# DA14586 register map
Vendor: Dialog; Series: DA1458x; File version: 1.2
CPU: CM0 r1p0, little endian, MPU, FPU, 3 interrupt priority bits
Registers are 16-bit, read-write, reset 0x0 unless marked. A register's access mark holds for its fields unless they carry their own. Offsets are from the block's base; [hi:lo] are bit positions; 'fields as' and 'values as' point back to an identical list.

## r_rfcu580_nl01 — r_rfcu580_nl01 registers
Base 0x50002000
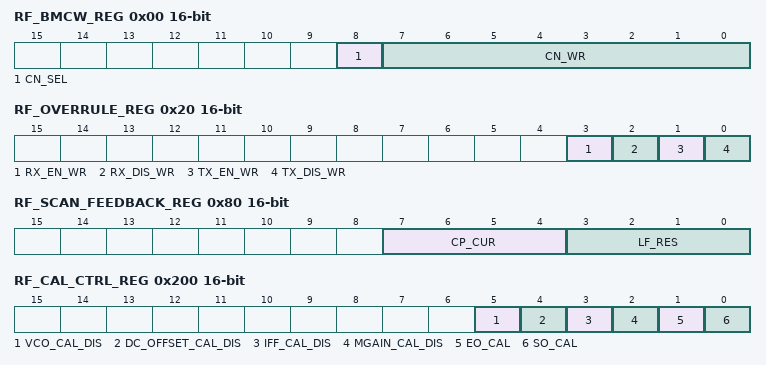
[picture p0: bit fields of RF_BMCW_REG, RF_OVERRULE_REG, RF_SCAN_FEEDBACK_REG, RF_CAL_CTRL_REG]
0x00 RF_BMCW_REG — Changed functionality of bits [7:6]
  [8] CN_SEL — Select between: 1 = use CN_WR as channel number 0 = use BLE Frequency word (normal function).
  [7:0] CN_WR — [7:6] = offset to RFCAL_CAP_WR, coarse calibraton LUT [5:0] = channel number
0x20 RF_OVERRULE_REG
  [3] RX_EN_WR — Enable rx_en
  [2] RX_DIS_WR — Disable rx_en
  [1] TX_EN_WR — Enable tx_en
  [0] TX_DIS_WR — Disable tx_en
0x40 RF_CALSTATE_REG
  [3:0] CALSTATE ro — Value of the calstate state machine
0x60 RF_CALCAP1_REG
  [15:0] VCO_CALCAP_LOW ro — Lowest 16 bits of vco_calcap
0x62 RF_CALCAP2_REG
  [1:0] VCO_CALCAP_HIGH ro — Highest 2 bits of vco_calcap.
0x80 RF_SCAN_FEEDBACK_REG
  [7:4] CP_CUR ro — Cp_cur value during scan.
  [3:0] LF_RES ro — Lf_res value during scan.
0x200 RF_CAL_CTRL_REG
  [5] VCO_CAL_DIS — Do not calibrate the VCO during Cal cycle
  [4] DC_OFFSET_CAL_DIS — Do not calibrate the VGA2 Offset during Cal cycle
  [3] IFF_CAL_DIS — Do not calibrate the IFF center frequency during Cal cycle
  [2] MGAIN_CAL_DIS — Do not calibrate the VCO and Modulation Gain during Cal cycle
  [1] EO_CAL ro — End of calibration trigger. Reading returns the eo_cal status signal which can be cleared by writing to RF_IRQ_CTRL_REG.EO_CAL_CLEAR
  [0] SO_CAL — Start of calibration trigger.Writing a 1 starts calibration.1Reading returns the calibration status (1 = busy calibrating).
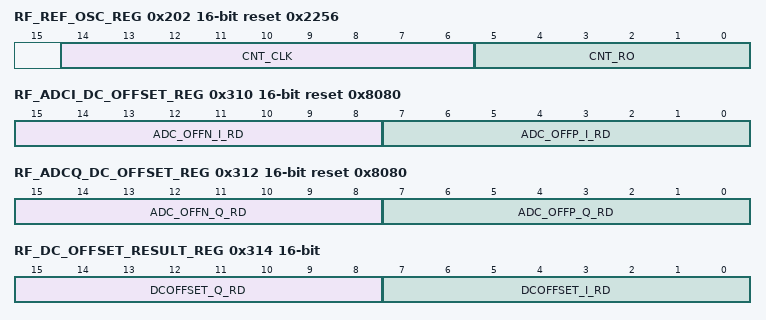
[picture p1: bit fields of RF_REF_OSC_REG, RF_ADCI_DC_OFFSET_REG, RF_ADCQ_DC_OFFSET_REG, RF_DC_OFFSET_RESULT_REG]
0x202 RF_REF_OSC_REG reset 0x2256
  [14:6] CNT_CLK — number of clock pulses corresponding to the value of CNT_RO
  [5:0] CNT_RO — number of reference oscillator periods that need to be counted
0x204 RF_IRQ_CTRL_REG reset 0x1
  [0] EO_CAL_CLEAR ro — Writing any value to this bit clears eo_cal interrupt.
0x300 RF_IFF_RESULT_REG reset 0x10 — Must be Retained
  [4:0] IF_CAL_CAP_RD ro — IF calibration result capacitance.
0x310 RF_ADCI_DC_OFFSET_REG reset 0x8080 — Must be Retained
  [15:8] ADC_OFFN_I_RD ro — DC offset compensation in the I path (inverting input) in sign-magnitude notarion (i.e. -31 : 1 : 31 mV)
  [7:0] ADC_OFFP_I_RD ro — DC offset compensation in the I path (non-inverting input) in sign-magnitude notarion (i.e. -31 : 1 : 31 mV)
0x312 RF_ADCQ_DC_OFFSET_REG reset 0x8080 — Must be Retained
  [15:8] ADC_OFFN_Q_RD ro — DC offset compensation in the Q path (inverting input) in sign-magnitude notarion (i.e. -31 : 1 : 31 mV)
  [7:0] ADC_OFFP_Q_RD ro — DC offset compensation in the Q path (non-inverting input) in sign-magnitude notarion (i.e. -31 : 1 : 31 mV)
0x314 RF_DC_OFFSET_RESULT_REG — Must be Retained
  [15:8] DCOFFSET_Q_RD ro — DC offset compensation value in Q channel valid when DCOFFSET_SEL = 0
  [7:0] DCOFFSET_I_RD ro — DC offset compensation value in I channel valid when DCOFFSET_SEL = 0.
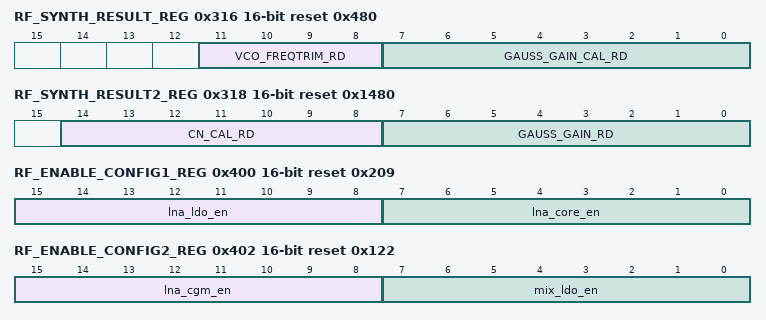
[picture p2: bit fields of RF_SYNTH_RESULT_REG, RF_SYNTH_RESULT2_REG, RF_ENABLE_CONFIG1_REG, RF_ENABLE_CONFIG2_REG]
0x316 RF_SYNTH_RESULT_REG reset 0x480 — Must be Retained
  [11:8] VCO_FREQTRIM_RD ro — Result of the VCO calibration (Not Retained)
  [7:0] GAUSS_GAIN_CAL_RD ro — Result of the modulation gain calibration (Retained)
0x318 RF_SYNTH_RESULT2_REG reset 0x1480 — Must be Retained
  [14:8] CN_CAL_RD ro — Result of the modulation gain calibration (Retained)
  [7:0] GAUSS_GAIN_RD ro — Modulation gain after trimming (Not Retained)
0x31A RF_SYNTH_RESULT3_REG reset 0xFFFF
  [15:0] MDSTATE_RD ro — Content of the calibration counter
0x400 RF_ENABLE_CONFIG1_REG reset 0x209
  [15:8] lna_ldo_en — Timing configuration for enable of the lna ldo
  [7:0] lna_core_en — Timing configuration for enable of the lna core
0x402 RF_ENABLE_CONFIG2_REG reset 0x122
  [15:8] lna_cgm_en — Timing configuration for enable of the lna cgm
  [7:0] mix_ldo_en — Timing configuration for enable of the mix ldo
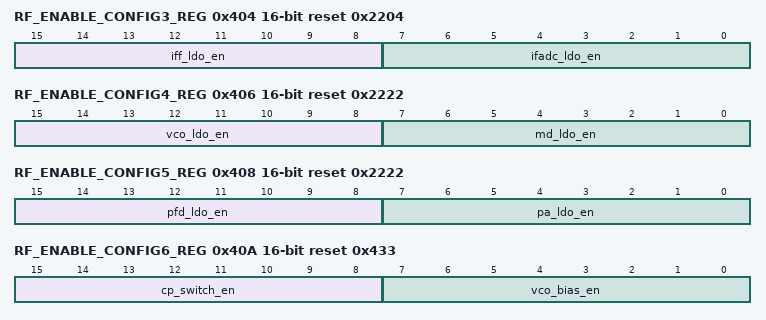
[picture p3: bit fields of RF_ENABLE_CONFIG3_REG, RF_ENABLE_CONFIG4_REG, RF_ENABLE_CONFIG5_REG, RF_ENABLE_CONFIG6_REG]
0x404 RF_ENABLE_CONFIG3_REG reset 0x2204
  [15:8] iff_ldo_en — Timing configuration for enable of the iff ldo
  [7:0] ifadc_ldo_en — Timing configuration for enable of the ifadc ldo
0x406 RF_ENABLE_CONFIG4_REG reset 0x2222
  [15:8] vco_ldo_en — Timing configuration for enable of the vco ldo
  [7:0] md_ldo_en — Timing configuration for enable of the md ldo
0x408 RF_ENABLE_CONFIG5_REG reset 0x2222
  [15:8] pfd_ldo_en — Timing configuration for enable of the pfd ldo
  [7:0] pa_ldo_en — Timing configuration for enable of the pa ldo
0x40A RF_ENABLE_CONFIG6_REG reset 0x433
  [15:8] cp_switch_en — Timing configuration for the dynamic CP current switching
  [7:0] vco_bias_en — Timing configuration for the VCO bias
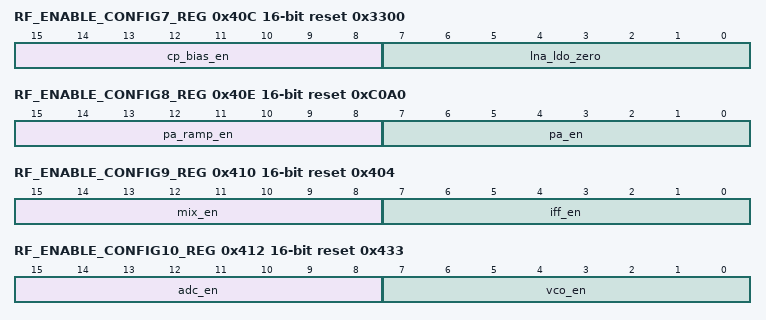
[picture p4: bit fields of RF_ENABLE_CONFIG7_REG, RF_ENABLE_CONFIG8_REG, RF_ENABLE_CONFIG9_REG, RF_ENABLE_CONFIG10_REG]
0x40C RF_ENABLE_CONFIG7_REG reset 0x3300
  [15:8] cp_bias_en — Timing configuration for enable of the CP bias
  [7:0] lna_ldo_zero — autozero control signal of the lna ldo
0x40E RF_ENABLE_CONFIG8_REG reset 0xC0A0
  [15:8] pa_ramp_en — Timing configuration for enable of the PA ramp
  [7:0] pa_en — Timing configuration for enable of the PA
0x410 RF_ENABLE_CONFIG9_REG reset 0x404
  [15:8] mix_en — Timing configuration for enable of the mixer
  [7:0] iff_en — Timing configuration for enable of the iff
0x412 RF_ENABLE_CONFIG10_REG reset 0x433
  [15:8] adc_en — Timing configuration for enable of the ADC
  [7:0] vco_en — Timing configuration for enable of the VCO
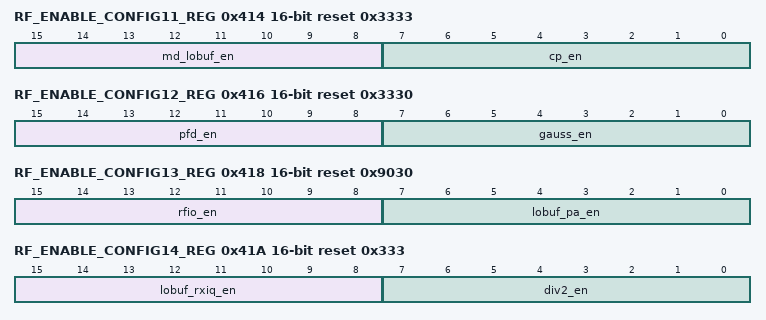
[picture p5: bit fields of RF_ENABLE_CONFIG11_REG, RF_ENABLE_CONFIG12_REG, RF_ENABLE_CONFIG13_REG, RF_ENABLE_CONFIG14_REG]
0x414 RF_ENABLE_CONFIG11_REG reset 0x3333
  [15:8] md_lobuf_en — Timing configuration for enable of main divider of the LO buffer
  [7:0] cp_en — Timing configuration for enable of CP
0x416 RF_ENABLE_CONFIG12_REG reset 0x3330
  [15:8] pfd_en — Timing configuration for the phase frequency detector
  [7:0] gauss_en — Timing configuration for the gauss module
0x418 RF_ENABLE_CONFIG13_REG reset 0x9030
  [15:8] rfio_en — Timing configuration for the rfio
  [7:0] lobuf_pa_en — Timing configuration for the PA lobuffer
0x41A RF_ENABLE_CONFIG14_REG reset 0x333
  [15:8] lobuf_rxiq_en — Timing configuration for the rxi lobuffer
  [7:0] div2_en — Timing configuration for the 2 divider
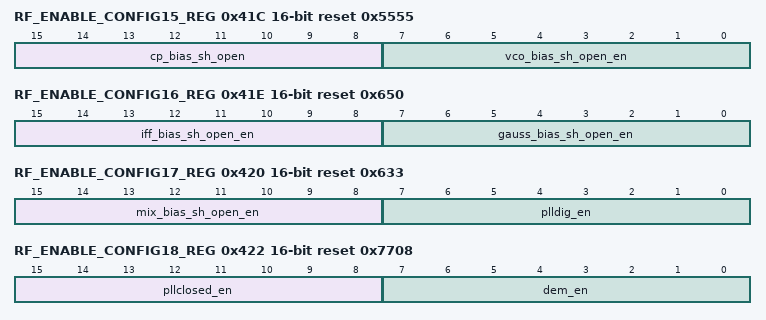
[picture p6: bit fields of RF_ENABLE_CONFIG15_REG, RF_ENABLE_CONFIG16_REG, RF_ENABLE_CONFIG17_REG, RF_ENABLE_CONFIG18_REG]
0x41C RF_ENABLE_CONFIG15_REG reset 0x5555
  [15:8] cp_bias_sh_open — Timing configuration for the CP bias S/H switch
  [7:0] vco_bias_sh_open_en — Timing configuration for the VCO bias S/H switch
0x41E RF_ENABLE_CONFIG16_REG reset 0x650
  [15:8] iff_bias_sh_open_en — Timing configuration for iffmix bias S/H switch
  [7:0] gauss_bias_sh_open_en — Timing configuration for gauss bias S/H switch
0x420 RF_ENABLE_CONFIG17_REG reset 0x633
  [15:8] mix_bias_sh_open_en — Timing configuration for pa bias S/H switch
  [7:0] plldig_en — Timing configuration for the plldig
0x422 RF_ENABLE_CONFIG18_REG reset 0x7708
  [15:8] pllclosed_en — Timing configuration for pllclosed
  [7:0] dem_en — Timing configuration for demodulator
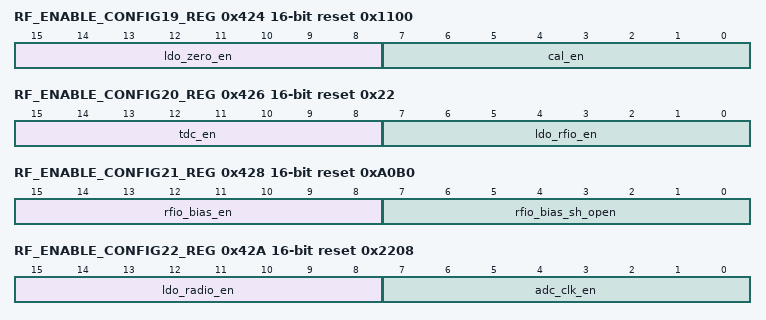
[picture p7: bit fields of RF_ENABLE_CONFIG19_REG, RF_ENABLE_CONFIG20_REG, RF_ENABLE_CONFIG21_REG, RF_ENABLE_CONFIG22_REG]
0x424 RF_ENABLE_CONFIG19_REG reset 0x1100
  [15:8] ldo_zero_en — Timing configuration for radio LDO auto zero enable
  [7:0] cal_en — Timing configuration for calibration slot
0x426 RF_ENABLE_CONFIG20_REG reset 0x22
  [15:8] tdc_en — Timing configuration for time to digital converter
  [7:0] ldo_rfio_en — Timing configuration for RFIO LDO
0x428 RF_ENABLE_CONFIG21_REG reset 0xA0B0
  [15:8] rfio_bias_en — Timing configuration for bias block for RFIO and RFPA
  [7:0] rfio_bias_sh_open — Timing configuration for S/H switch of bias block for RFIO/RFPA
0x42A RF_ENABLE_CONFIG22_REG reset 0x2208
  [15:8] ldo_radio_en — Timing configuration for LDO for the radio IO buffer
  [7:0] adc_clk_en — Timing configuration for the enable of the ADC clock
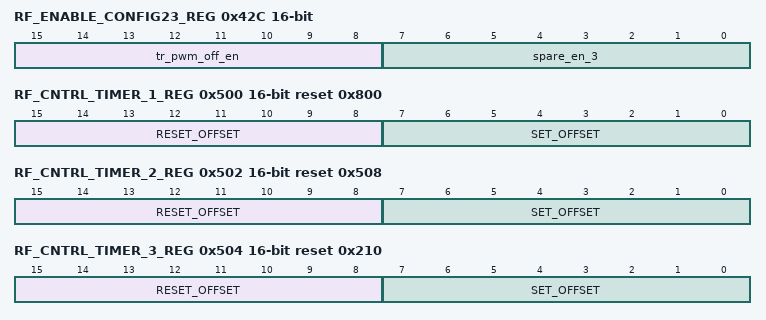
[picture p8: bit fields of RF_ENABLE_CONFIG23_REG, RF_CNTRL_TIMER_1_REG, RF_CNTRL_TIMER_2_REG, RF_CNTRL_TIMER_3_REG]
0x42C RF_ENABLE_CONFIG23_REG
  [15:8] tr_pwm_off_en — Timing configuration for tr_pwm_off_en
  [7:0] spare_en_3 — Timing configuration for spare_en_3
0x500 RF_CNTRL_TIMER_1_REG reset 0x800
  [15:8] RESET_OFFSET — Offset w.r.t. end switch instant eo_rx/eo_tx
  [7:0] SET_OFFSET — Offset w.r.t. start switch instant so_rx/so_tx.
0x502 RF_CNTRL_TIMER_2_REG reset 0x508
  [15:8] RESET_OFFSET — Offset w.r.t. end switch instant eo_rx/eo_tx.
  [7:0] SET_OFFSET — Offset w.r.t. start switch instant so_rx/so_tx.
0x504 RF_CNTRL_TIMER_3_REG reset 0x210
  fields as RF_CNTRL_TIMER_2_REG
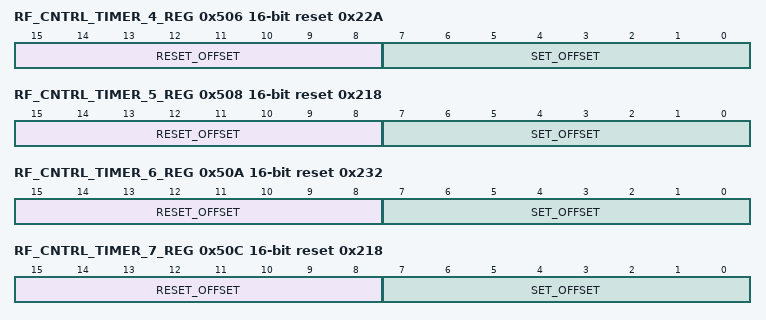
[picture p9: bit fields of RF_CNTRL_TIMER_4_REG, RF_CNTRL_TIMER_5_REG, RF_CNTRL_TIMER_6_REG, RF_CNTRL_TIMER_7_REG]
0x506 RF_CNTRL_TIMER_4_REG reset 0x22A
  [15:8] RESET_OFFSET — Offset w.r.t. end switch instant eo_rx/eo_tx.
  [7:0] SET_OFFSET — Offset w.r.t. start switch instant so_rx/eo_tx.
0x508 RF_CNTRL_TIMER_5_REG reset 0x218
  fields as RF_CNTRL_TIMER_4_REG
0x50A RF_CNTRL_TIMER_6_REG reset 0x232
  fields as RF_CNTRL_TIMER_4_REG
0x50C RF_CNTRL_TIMER_7_REG reset 0x218
  [15:8] RESET_OFFSET — Offset w.r.t. end switch instant eo_tx/eo_tx.
  [7:0] SET_OFFSET — Offset w.r.t. start switch instant so_tx/eo_tx.
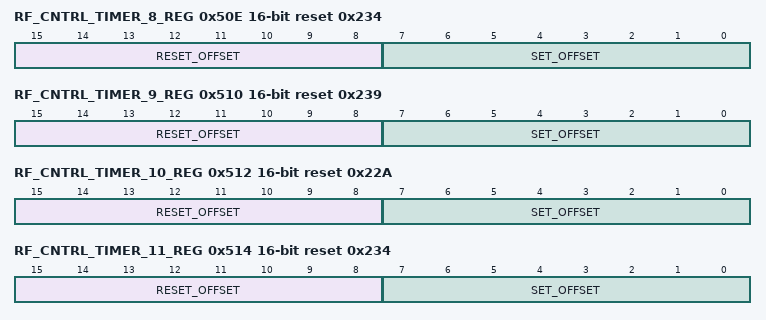
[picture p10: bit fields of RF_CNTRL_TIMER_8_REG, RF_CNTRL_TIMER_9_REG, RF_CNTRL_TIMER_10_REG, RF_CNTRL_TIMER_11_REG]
0x50E RF_CNTRL_TIMER_8_REG reset 0x234
  fields as RF_CNTRL_TIMER_4_REG
0x510 RF_CNTRL_TIMER_9_REG reset 0x239
  fields as RF_CNTRL_TIMER_4_REG
0x512 RF_CNTRL_TIMER_10_REG reset 0x22A
  fields as RF_CNTRL_TIMER_4_REG
0x514 RF_CNTRL_TIMER_11_REG reset 0x234
  fields as RF_CNTRL_TIMER_7_REG
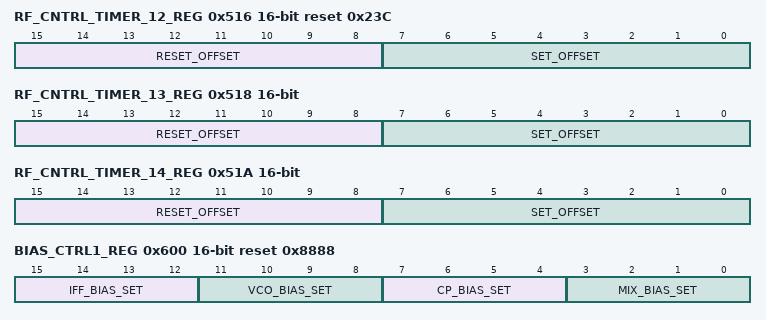
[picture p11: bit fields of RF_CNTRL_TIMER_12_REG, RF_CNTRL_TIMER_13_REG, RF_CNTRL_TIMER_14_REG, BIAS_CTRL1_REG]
0x516 RF_CNTRL_TIMER_12_REG reset 0x23C
  fields as RF_CNTRL_TIMER_4_REG
0x518 RF_CNTRL_TIMER_13_REG
  fields as RF_CNTRL_TIMER_4_REG
0x51A RF_CNTRL_TIMER_14_REG
  fields as RF_CNTRL_TIMER_4_REG
0x600 BIAS_CTRL1_REG reset 0x8888
  [15:12] IFF_BIAS_SET — Tuning of the IF filter bias current
  [11:8] VCO_BIAS_SET — Tuning of the VCO bias current
  [7:4] CP_BIAS_SET — Tuning of the charge pump bias current
  [3:0] MIX_BIAS_SET — Tuning of the mixer bias current
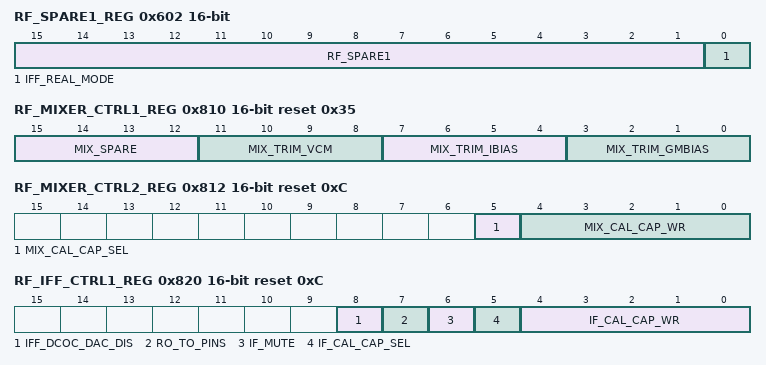
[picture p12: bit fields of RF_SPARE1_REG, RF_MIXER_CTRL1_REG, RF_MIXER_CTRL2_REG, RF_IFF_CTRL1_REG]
0x602 RF_SPARE1_REG
  [15:1] RF_SPARE1 — Spare bits for radio
  [0] IFF_REAL_MODE — Choose the transfer function mode of the IFF 0: Normal operation (complex) 1: Test mode (real, approx. 16 dB less gain at 1 MHz than in complex mode);
0x810 RF_MIXER_CTRL1_REG reset 0x35
  [15:12] MIX_SPARE — Spare registers for mixer control
  [11:8] MIX_TRIM_VCM — Trim the common mode voltage at the input of the TIA 0: Minimum voltage 8: Nominal voltage F: Maximal voltage
  [7:4] MIX_TRIM_IBIAS — Trim the bias current of the TIA 0: Minimum bias current 8: Nominal bias current F: Maximal bias current
  [3:0] MIX_TRIM_GMBIAS — Trim the Mixer bias resistor for optimum transcunductance 0: Minimum transconductance 8: Nominal transconductance F: Maximal transconductance
0x812 RF_MIXER_CTRL2_REG reset 0xC
  [5] MIX_CAL_CAP_SEL — '0': Normal operation: use IF_CAL_CAP_RD (as determined by IF calibration) for the loop filter capacitance; '1': use the value written to MIX_CAL_CAP_WR
  [4:0] MIX_CAL_CAP_WR — External value for calibration of mixer pole capacitance
0x820 RF_IFF_CTRL1_REG reset 0xC
  [8] IFF_DCOC_DAC_DIS — Disable the DC offset current DAC
  [7] RO_TO_PINS — '0': normal operation; '1': Enable reference oscillator.
  [6] IF_MUTE — '0': normal operation; '1': Mute IFF by short circuit of VGA1 input. Note: set TGATE_MIXER_IF to '0' for isolation from the IRM
  [5] IF_CAL_CAP_SEL — '0': use value as determined by IF calibration for IF filter; '1': use the value written to IF_CAL_CAP for IF filter.
  [4:0] IF_CAL_CAP_WR — External value for IF calibration capacitance
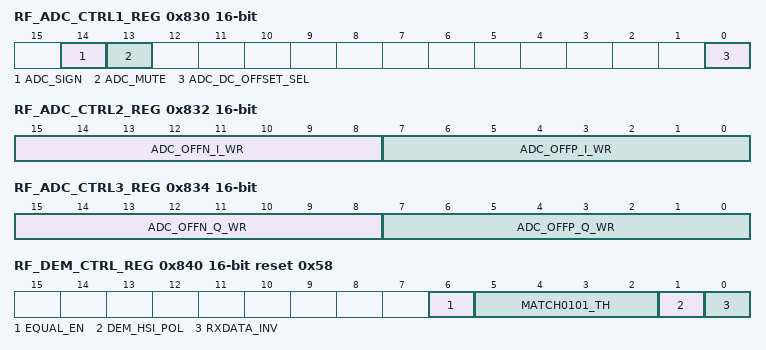
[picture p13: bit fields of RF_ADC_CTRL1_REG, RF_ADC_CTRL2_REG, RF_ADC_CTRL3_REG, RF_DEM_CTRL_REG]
0x830 RF_ADC_CTRL1_REG
  [14] ADC_SIGN — Change polarity of ADC input.
  [13] ADC_MUTE — 0: Normal operation 1: Short the inputs of the ADC (used for DC offset cal)
  [0] ADC_DC_OFFSET_SEL — 0: Normal operation (i.e. Use automatically calibrated value) 1: Use ADC_OFFx_y_WR to set the DC offset compensation values in the ADC (x = N or P, y = I or Q
0x832 RF_ADC_CTRL2_REG
  [15:8] ADC_OFFN_I_WR — External value for the DC offset compensation in the I path negative side. With common mode input voltage at Vpwrp/2, this value is 512-ADC_OFFP_Q_WR.
  [7:0] ADC_OFFP_I_WR — External value for the DC offset compensation in the I path positive side.
0x834 RF_ADC_CTRL3_REG
  [15:8] ADC_OFFN_Q_WR — External value for the DC offset compensation in the Q path negative side. With common mode input voltage at Vpwrp/2, this value is 512-ADC_OFFP_Q_WR.
  [7:0] ADC_OFFP_Q_WR — External value for the DC offset compensation in the Q path positive side.
0x840 RF_DEM_CTRL_REG reset 0x58
  [6] EQUAL_EN — Enable the equalizer in the demodulator
  [5:2] MATCH0101_TH — Threshold for the 0101 pattern matching
  [1] DEM_HSI_POL — Invert 'frequency' polarity of the demodulator
  [0] RXDATA_INV — '0': Normal operation '1': Invert the polarity of the received bits
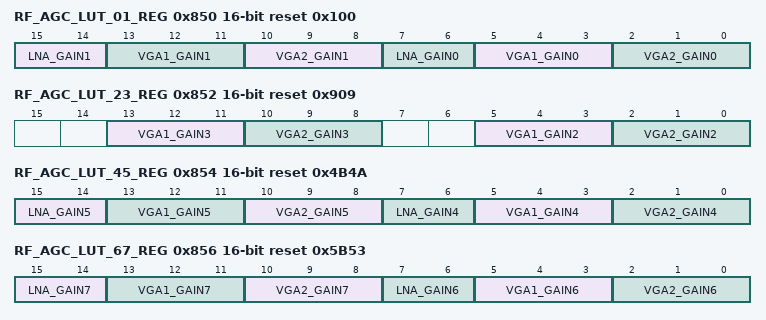
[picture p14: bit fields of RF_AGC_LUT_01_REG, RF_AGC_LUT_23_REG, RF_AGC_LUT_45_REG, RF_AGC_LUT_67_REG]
0x850 RF_AGC_LUT_01_REG reset 0x100
  [15:14] LNA_GAIN1 — LNA gain setting while in AGC setting 0
  [13:11] VGA1_GAIN1 — VGA1 gain setting while in AGC setting 1
  [10:8] VGA2_GAIN1 — VGA2 gain setting while in AGC setting 1
  [7:6] LNA_GAIN0 — LNA gain setting while in AGC setting 0
  [5:3] VGA1_GAIN0 — VGA1 gain setting while in AGC setting 0
  [2:0] VGA2_GAIN0 — VGA2 gain setting while in AGC setting 0
0x852 RF_AGC_LUT_23_REG reset 0x909
  [13:11] VGA1_GAIN3 — VGA1 gain setting while in AGC setting 3
  [10:8] VGA2_GAIN3 — VGA2 gain setting while in AGC setting 3
  [5:3] VGA1_GAIN2 — VGA1 gain setting while in AGC setting 2
  [2:0] VGA2_GAIN2 — VGA2 gain setting while in AGC setting 2
0x854 RF_AGC_LUT_45_REG reset 0x4B4A
  [15:14] LNA_GAIN5 — LNA gain setting while in AGC setting 5
  [13:11] VGA1_GAIN5 — VGA1 gain setting while in AGC setting 5
  [10:8] VGA2_GAIN5 — VGA2 gain setting while in AGC setting 5
  [7:6] LNA_GAIN4 — LNA gain setting while in AGC setting 4
  [5:3] VGA1_GAIN4 — VGA1 gain setting while in AGC setting 4
  [2:0] VGA2_GAIN4 — VGA2 gain setting while in AGC setting 4
0x856 RF_AGC_LUT_67_REG reset 0x5B53
  [15:14] LNA_GAIN7 — LNA gain setting while in AGC setting 7
  [13:11] VGA1_GAIN7 — VGA1 gain setting while in AGC setting 7
  [10:8] VGA2_GAIN7 — VGA2 gain setting while in AGC setting 7
  [7:6] LNA_GAIN6 — LNA gain setting while in AGC setting 6
  [5:3] VGA1_GAIN6 — VGA1 gain setting while in AGC setting 6
  [2:0] VGA2_GAIN6 — VGA2 gain setting while in AGC setting 6
0x858 RF_AGC_LUT_89_REG reset 0x6B63
  [15:14] LNA_GAIN9 — LNA gain setting while in AGC setting 9
  [13:11] VGA1_GAIN9 — VGA1 gain setting while in AGC setting 9
  [10:8] VGA2_GAIN9 — VGA2 gain setting while in AGC setting 9
  [7:6] LNA_GAIN8 — LNA gain setting while in AGC setting 8
  [5:3] VGA1_GAIN8 — VGA1 gain setting while in AGC setting 8
  [2:0] VGA2_GAIN8 — VGA2 gain setting while in AGC setting 8
0x860 RF_AGC_CTRL1_REG reset 0x980B
  [15:14] AGC_MODE — Choose the method to use for AGC evaluation Description TBD
  [13:7] AGC_TH_HIGH — AGC hysteresis high threshold (switch up one AGC_SETTING_R step when exceeding this level)
  [6:0] AGC_TH_LOW — AGC hysteresis low threshold (switch down one AGC_SETTING_R step when dropping below this level)
0x862 RF_AGC_CTRL2_REG reset 0x3
  [12] SLOW_AGC — Enable the slow AGC mode (no consecutive AGC setting switches)
  [11:8] AGCSETTING_WR — Fixed AGC setting to be used to configure LNA, VGA1 and VGA2 when AGCSETTING_SEL = 1 0: Highest gain as configured in RF_AGC_LUT_01_REG 1: Lower gain as configured in RF_AGC_LUT_01_REG 2: Still lower gain as configured in RF_AGC_LUT_23_REG ... 9-F: Lowest gain as configured in RF_AGC_LUT_89_REG
  [7] AGCSETTING_SEL — LNA, VGA1 and VGA2 gains '0': controlled by AGC'1': provided manually through AGCSETTING_WR
  [6] EN_FRZ_GAIN — '0': AGC always active'1': Freeze gain after Access Address detection
  [5:0] RSSI_TH — RSSI threshold for the packet detection
0x864 RF_AFC_CTRL_REG reset 0xF5
  [7:6] POLE2 — Choose the method to use for AFC tracking during the slot Description TBD
  [5:4] POLE1 — Choose the method to use for AFC tracking during the slot Description TBD
  [3:0] AFC_MODE — Choose the method to use for AFC tracking during the slot Description TBD
0x866 RF_DC_OFFSET_CTRL1_REG reset 0x8080
  [15:8] DCOFFSET_Q_WR — DC offset compensation value in Q channel valid when DCOFFSET_SEL = 1
  [7:0] DCOFFSET_I_WR — DC offset compensation value in I channel valid when DCOFFSET_SEL = 1
0x868 RF_DC_OFFSET_CTRL2_REG reset 0x130
  [8:7] DCNGAIN — Number of gain settings for the full DC offset calibration
  [6:4] DCNSTEP — Number of the steps per.gain setting for the full or partial DC offset calibrations
  [3:2] DCPOLE — Selects the pole of the digital high pass fitlers Encoding: TBD
  [1] DCPARCAL_EN — Enable flag for the partial DC offset calibration (executed when the demodulator is enabled).
  [0] DCOFFSET_SEL — '0': Normal operation '1': Use the manual DC offset compensation values from RF_DC_OFFSET_CTRL1_REG
0x86A RF_DC_OFFSET_CTRL3_REG reset 0xB411
  [15:8] DCBETA_Q — Quadrature feedback gain for the DC offset calibration
  [7:0] DCBETA_I — Inphase feedback gain for the DC offset calibration
0x86C RF_DC_OFFSET_CTRL4_REG reset 0x9920
  [15:12] DCAGCSETTING_FULL3 — AGC setting for forth last the gain step for the full DC offset calibration
  [11:8] DCAGCSETTING_FULL2 — AGC setting for third last the gain step for the full DC offset calibration
  [7:4] DCAGCSETTING_FULL1 — AGC setting for second last the gain step for the full DC offset calibration
  [3:0] DCAGCSETTING_FULL0 — AGC setting for last the gain step for the full DC offset calibration
0x870 RF_RADIG_SPARE_REG
  [15:3] RADIG_SPARE — Spare bits to be defined later
0x900 RF_AGC_RESULT_REG
  [11:8] AGCSETTING_RD ro — AGC setting as automatically selected in receive mode to configure LNA, VGA1 and VGA2 0: Highest gain as configured in RF_AGC_LUT_01_REG 1: Lower gain as configured in RF_AGC_LUT_01_REG 2: Still lower gain as configured in RF_AGC_LUT_23_REG ... 9-F: Lowest gain as configured in RF_AGC_LUT_89_REG
  [7:0] AFC_RD ro — Frequency offset estimation (in 2s complement) with a resolution of approximately 5 kHz.
0x902 RF_RSSI_RESULT_REG
  [15:6] RSSI_AVG_RD ro — RSSI value measured in averaging mode in continuous RX mode (used for LNA selectivity calibration)
  [5:0] RSSI_PH_RD ro — RSSI value measured in peak-hold mode during the preamble and Access Addres detection
0xA00 RF_PA_CTRL_REG reset 0x7CD7 — Removed obsolete values of bits 10:7, pa_pw back to 4
  [14:11] LEVEL_LDO_RFPA — Control for PA supply voltage (output power)
  [6:5] PA_RAMPSPEED — Ramping speed setting of the driver stage: '0x0': slowest (1.25 uA) '0x1': 2x faster (2.5 uA) '0x2': default ramping speed '0x3': fastest
  [4:2] PA_PW — Pulse width setting to control HD2 '0': not active '1': 48.8 percent duty cycle '2': 49.4 percent duty cycle '3': 49.7 percent duty cycle '4': 50 percent duty cycle (default) '5': 50.3 percent duty cycle '6': 50.6 percent duty cycle '7': 51.2 percent duty cycle
  [1:0] PA_GAIN — Sets gain/DC Current setting of the differential to single ended converter '0': smallest current setting (60 uA) '1': current setting 1 (80 uA) '2': default (100 uA) '3': largest current setting (120 uA)
0xC00 RF_SYNTH_CTRL1_REG reset 0x2962
  [14] PLL_HSI_POL — High Side Injection polarity 0: LO frequency is lower than the wanted RF frequency 1: LO frequency is higher than the wanted RF frequency
  [13] CS — Channel Spacing 0: 1MHz 1: 2MHz
  [12] SGN — Sign bit for the channel step 0: positive 1: negative
  [11:0] CHANNEL_ZERO — Channel 0 frequency in MHz
0xC02 RF_SYNTH_CTRL2_REG reset 0x40B
  [12] BT_SEL — 0: BT = 0.5; 1: BT = 0.6
  [11] EO_PACKET_DIS — Disable the end of packet detection 0: End of packet detection enabled 1: End of pakcet detection disabled
  [10] TXDATA_INV — Select polarity of the modulation prior to the pulse shaping 0: Normal operation 1: Invert the modulation signal
  [9] GAUSS_86 — Select the output resolution in the analog signal path 0: 8 bit resolution for the shaping signal 1: 6 bit resolution for the shaping signal
  [8] GAUSS_INV — Select polarity of the analog modulation path 0: Normal operation 1: Invert the signal in the analog signal path
  [7:6] DELAY — Additional delay in analog signal path in RCLK cycles
  [5:4] MODINDEX — Modulation Index selection 0:h = 1/2 (Îf = 250 kHz) 1: h = 1/4 (Îf = 125 kHz) 2: h = 17/32 (Îf = 266 kHz) 3: h = 35/64 (Îf = 273 kHz)
  [3:2] SD_ORDER_TX — Order of the sigma-delta modulator in TX mode
  [1:0] SD_ORDER_RX — Order of the sigma-delta modulator in RX mode
0xC04 RF_SYNTH_CTRL3_REG reset 0x3
  [14] MODVAL_SEL — 0: Normal operation 1: Use the externally provided value for the modulation
  [13:0] MODVAL_WR — Externally provided modulation value in 2s complement Îf = 16 MHz x MODVAL_WR/16348
0xC06 RF_VCOCAL_CTRL_REG reset 0x3
  [6:5] VCOCAL_PERIOD — Length of a VCO calibration step 0: 1 us 1: 2 us 2: 3 us 3: 4 us
  [4] VCO_FREQTRIM_SEL — 0: Normal operation 1: Use VCO_FREQTRIM_WR for the VCO calibration
  [3:0] VCO_FREQTRIM_WR — Externally provided VCO calibration value
0xC08 RF_MGAIN_CTRL_REG
  [15:13] KMOD_ALPHA — Kmod channel dependent trimming constant. 0: No trimming is activated >0: The modulation gain in the direct path is modified with a factor: 1-SGNx(KMOD_ALPHA+2)x(CN-CN_CAL_RD)/2048
  [12:11] MGAIN_AVER — Average over a number of comparator output values 0: 1 value 1: 3 values 2: 5 values 3: 7 values
  [10] MGAIN_CMP_INV — Invert the output of the modulation gain comparator before usage.
  [9] MGAIN_DBL_TRANSMIT — Length of a modulation gain calibration step 0: 4 symbol periods 1: 8 symbol periods
  [8] GAUSS_GAIN_SEL — 0: Normal operation 1: Use GAUSS_GAIN_WR for the modulation gain
0xC0A RF_MGAIN_CTRL2_REG reset 0x10
  [6:0] MGAIN_TRANSMIT_LENGTH — Number of symbols for transmit0 and transmit1 length during mgain calibration.
0xC10 RF_MGC_CTRL_REG
  [3:2] GAUSS_DAC_CTRL — Reserved bits for Gauss DAC settings
  [1] MGC_POLE_SW — Switch in an aditional pole on the mgc amplifer to have extra filtering of the loopfilter voltage. '0': no pole (bandwidth limited by the opamp) '1': switch in pole to reduce amplifier bandwidth
  [0] MGC_GAIN_SET — Set the desired gain for the mgc calibration amplifier. '0': gain= 15x '1': gain= 10x
0xC20 RF_VCOVAR_CTRL_REG reset 0xA492
  [15:14] MOD_VAR_V1 — Bias voltage of the VCO Modulation varactor (high Vmod) 0: low 1: mid 2: nominal 3: high
  [13:12] MOD_VAR_V0 — Bias voltage of the VCO Modulation varactor (low Vmod) 0: low 1: mid 2: nominal 3: high
  [11:9] TUNE_VAR_V3 — Bias voltage of the VCO Tuning varactor (high Vtune) 001: low 010: nominal 100: high others: not allowed
  [8:6] TUNE_VAR_V2 — Bias voltage of the VCO Tuning varactor (high-mid Vtune) Coding identical to TUNE_VAR_V3
  [5:3] TUNE_VAR_V1 — Bias voltage of the VCO Tuning varactor (low-mid Vtune) Coding identical to TUNE_VAR_V3
  [2:0] TUNE_VAR_V0 — Bias voltage of the VCO Tuning varactor (low Vtune) Coding identical to TUNE_VAR_V3
0xC22 RF_VCO_CALCAP_BIT14_REG reset 0x559D — LUT entry for bit 14 of the VCO calibration capacitance
  [15:0] VCO_CALCAP_BIT14
0xC24 RF_VCO_CALCAP_BIT15_REG — LUT entry for bit 15 of the VCO calibration capacitance
  [15:0] VCO_CALCAP_BIT15
0xC40 RF_PFD_CTRL_REG
  [3] PFD_POLARITY — '0': Normal operation (UP: implies RCLK leads NCLK) '1': Inverted operation (UP: implies NCLK leads RCLK)
  [2] FIXED_CUR_EN — Enable manual override of PFD output '0': Normal operation '1': PFD ouput given by FIXED_CUR_SET
  [1:0] FIXED_CUR_SET — Set the PFD output in a fixed position such that the CP output current is constant'0': UP = 0, DN = 0 '1': UP = 0, DN = 1 '2': UP = 1, DN = 0 '3': UP = 1, DN = 1
0xC50 RF_CP_CTRL_REG reset 0xFFFF
  [15:12] CP_CUR_TX — CP current setting during PLL - Lock in TX mode 1111: 45 µA (fastest, setting 0) 0111: 15 µA (setting 1) 0011: 7.5 µA (setting 2) 0001: 3.75 µA (slowest, setting 3) Intermediate values are possible (but not recommended). Calculate the effective value with: bit 0: 3.75 µA bit 1: 3.75 µA bit 2: 7.5 µA bit 3: 30 µA
  [11:8] CP_CUR_RX — CP current setting during PLL - lock in RX mode same coding as for CP_CUR_TX
  [7:4] CP_CUR_SET_TX — Chargepump current setting during PLL settling in TX mode same coding as for CP_CUR_TX
  [3:0] CP_CUR_SET_RX — Chargepump current setting during PLL settling in RX mode. same coding as for CP_CUR_TX
0xC52 RF_LF_RES_CTRL_REG reset 0xFFFF — LF resistor setting
  [15:12] LF_RES_TX — Loopfilter resistor setting during PLL - Lock in TX mode 1xxx: 72 k (fastest, setting 0) 01xx: 120 k (setting 1) 001x: 168 k (setting2) 000x: 240 k (slowest, setting 3)
  [11:8] LF_RES_RX — Loopfilter resistor setting during PLL - Lock in RX mode same coding as for LF_RES_TX
  [7:4] LF_RES_SET_TX — Loopfilter resistor setting during PLL settling in TX mode same coding as for LF_RES_TX
  [3:0] LF_RES_SET_RX — Loopfilter resistor setting during PLL settling in RX mode same coding as for LF_RES_TX
0xC60 RF_LF_CTRL_REG reset 0xC
  [6] LF_SHORT_R4 — '0': R4 in place, '1': R4 shorted, C2 and C4 in parallel.
  [5] LF_CAL_CAP_SEL — '0': Normal operation: use IF_CAL_CAP_RD (as determined by IF calibration) for the loop filter capacitance; '1': use the value written to LF_CAL_CAP_WR
  [4:0] LF_CAL_CAP_WR — External value for loop filter calibration capacitance
0xC70 RF_TDC_CTRL_REG — TDC settings
  [12] TDC_CONNECT — '0': Normal Operation (no measurement possible) '1': Connect the PFD inputs also to the TDC inputs
  [11:10] REF_CTRL — Select how calibration is performed. Phase 1: '0': Count during 1 RCLK period (expect 60-70 as result) '1': Count during 2 RCLK period (expect 120-140 as result) '2': Count during 3 RCLK period (expect 180 -210 as result) '3': not allowed Phase 2, base the resolution measurement on: '0': 1 overlap of fast and slow oscillators (NF=NS+1) '1': 2 overlaps of fast and slow oscillators (NF=NS+2) '2': 1 overlap of fast and slow oscillators (NF=NS+1) '3': Not allowed
  [9] CAL_PH_2 — Select calibration option 2 '0': normal operation (pfd measurement mode or cal mode 1) '1': measure the slow - fast oscillator period (calibration phase 2) ------- Note CAL_PH_1 must be 0 in this setting
  [8] CAL_PH_1 — Select calibration option 1 '0': normal operation (pfd measurement or cal mode 2) '1': measure the fast oscillator period (calibration phase 1) ------- Note: CAL_PH_2 must be 0 in this setting
  [7:4] CTRL_SLOW — Trim the slow oscillator '0': Minimum frequency (default) 'F': Maximum frequency
  [3:0] CTRL_FAST — Trim the fast oscillator '0': mimimum frequency 'F': maximum frequency
